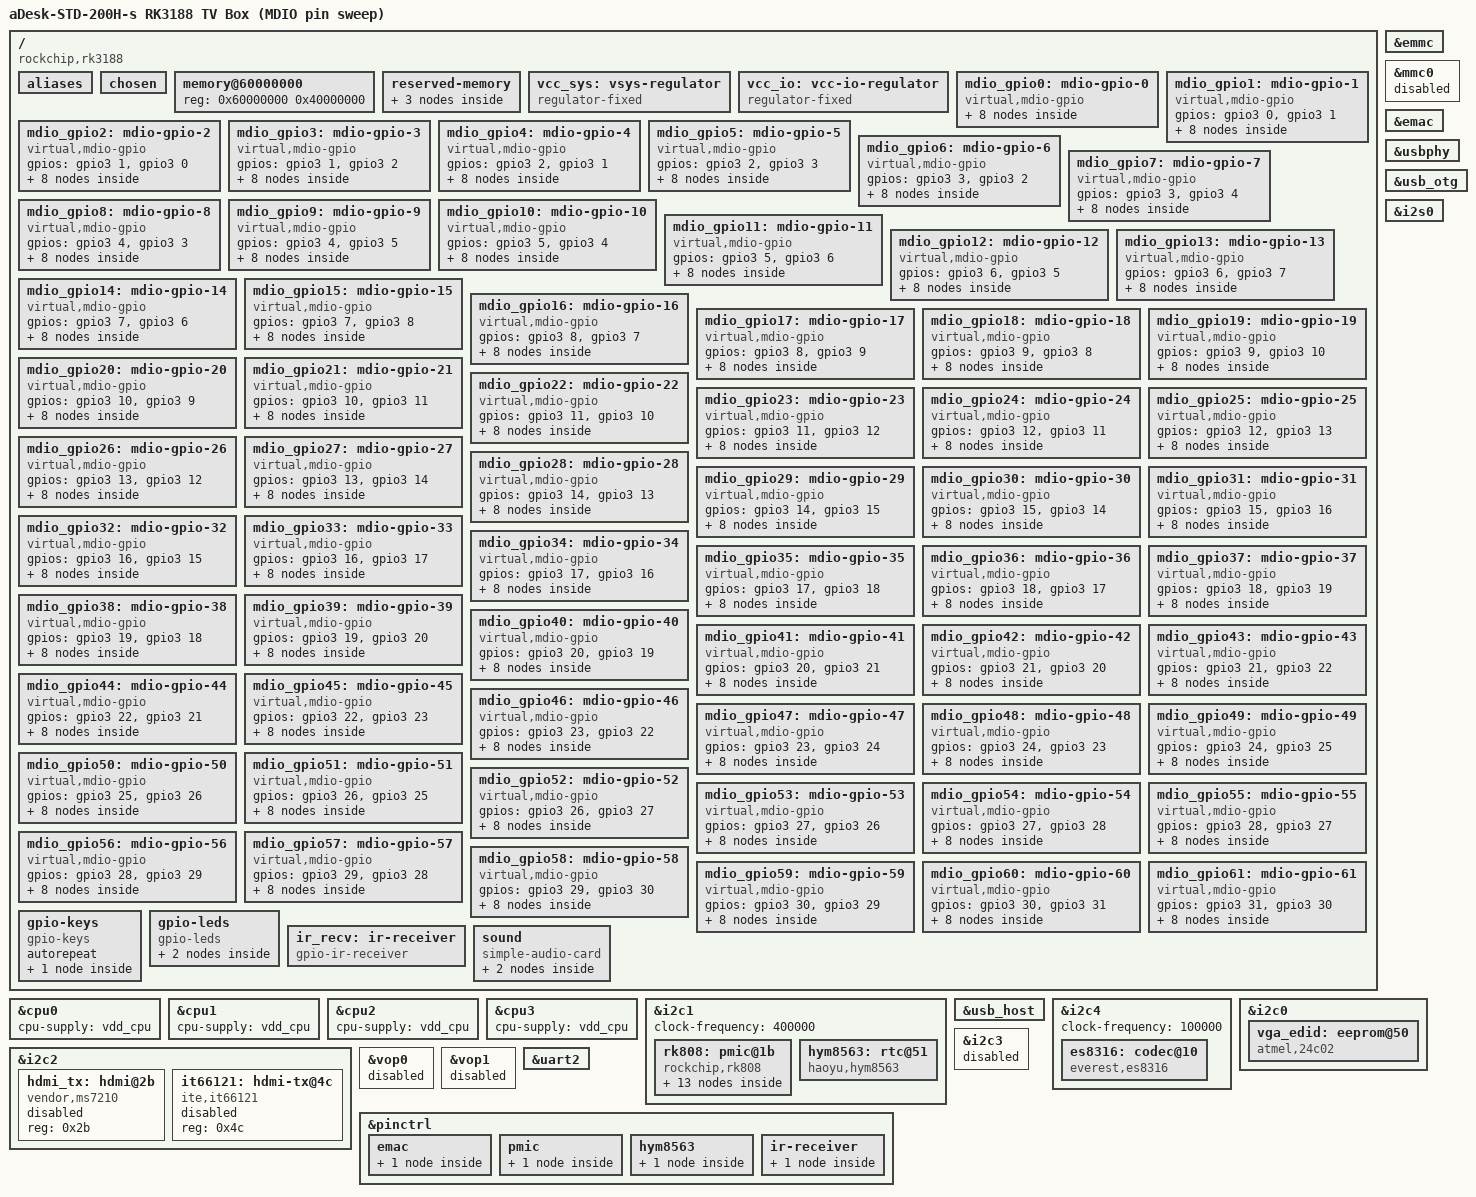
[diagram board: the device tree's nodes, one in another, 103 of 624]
// SPDX-License-Identifier: (GPL-2.0+ OR MIT)
/dts-v1/;
/*
 * 【诊断专用】MDIO 引脚扫频版（不是最终版）
 * 背景：RTL8201FN 在 GPIO3_D0/D1 上，硬件 MDIO（ttl-17）和软件 bit-bang（ttl-19）
 * 都扫不到 0~7 任一地址；而 RJ45 指示灯亮，说明 PHY 有电、链路正常。
 * 做法：在 GPIO3 组（pin 96~127 = A0~D7）内，把所有【相邻引脚对】的正反两种极性
 * 各挂一条 mdio-gpio 总线（共 62 条），每条都扫 0~7 号地址。
 * 判读：哪一条总线打出“不是 missing”的地址，那两只脚就是真的 MDC/MDIO，
 * 且那个地址就是 PHY 真实地址。找到后改回单总线正式版。
 */

#include <dt-bindings/gpio/gpio.h>
#include <dt-bindings/input/input.h>
#include <dt-bindings/interrupt-controller/irq.h>
#include <dt-bindings/pinctrl/rockchip.h>
#include "rk3188.dtsi"

/ {
	model = "aDesk-STD-200H-s RK3188 TV Box (MDIO pin sweep)";
	compatible = "rockchip,rk3188";

	aliases {
		/* 物理 TTL 接 UART2（0x20064000）；uart2 由 dtsi 默认 alias serial2 映射为 ttyS2 */
		serial0 = &uart0;
		serial2 = &uart2;
		/* mdio-gpio 总线别名：驱动靠它取 bus id（of_alias_get_id(node,"mdio-gpio")），
		 * 没有这行只会打印一句 failed to get alias id 然后 id=0，功能不受影响 */
		mdio-gpio0 = &mdio_gpio0;
		mdio-gpio1 = &mdio_gpio1;
		mdio-gpio2 = &mdio_gpio2;
		mdio-gpio3 = &mdio_gpio3;
		mdio-gpio4 = &mdio_gpio4;
		mdio-gpio5 = &mdio_gpio5;
		mdio-gpio6 = &mdio_gpio6;
		mdio-gpio7 = &mdio_gpio7;
		mdio-gpio8 = &mdio_gpio8;
		mdio-gpio9 = &mdio_gpio9;
		mdio-gpio10 = &mdio_gpio10;
		mdio-gpio11 = &mdio_gpio11;
		mdio-gpio12 = &mdio_gpio12;
		mdio-gpio13 = &mdio_gpio13;
		mdio-gpio14 = &mdio_gpio14;
		mdio-gpio15 = &mdio_gpio15;
		mdio-gpio16 = &mdio_gpio16;
		mdio-gpio17 = &mdio_gpio17;
		mdio-gpio18 = &mdio_gpio18;
		mdio-gpio19 = &mdio_gpio19;
		mdio-gpio20 = &mdio_gpio20;
		mdio-gpio21 = &mdio_gpio21;
		mdio-gpio22 = &mdio_gpio22;
		mdio-gpio23 = &mdio_gpio23;
		mdio-gpio24 = &mdio_gpio24;
		mdio-gpio25 = &mdio_gpio25;
		mdio-gpio26 = &mdio_gpio26;
		mdio-gpio27 = &mdio_gpio27;
		mdio-gpio28 = &mdio_gpio28;
		mdio-gpio29 = &mdio_gpio29;
		mdio-gpio30 = &mdio_gpio30;
		mdio-gpio31 = &mdio_gpio31;
		mdio-gpio32 = &mdio_gpio32;
		mdio-gpio33 = &mdio_gpio33;
		mdio-gpio34 = &mdio_gpio34;
		mdio-gpio35 = &mdio_gpio35;
		mdio-gpio36 = &mdio_gpio36;
		mdio-gpio37 = &mdio_gpio37;
		mdio-gpio38 = &mdio_gpio38;
		mdio-gpio39 = &mdio_gpio39;
		mdio-gpio40 = &mdio_gpio40;
		mdio-gpio41 = &mdio_gpio41;
		mdio-gpio42 = &mdio_gpio42;
		mdio-gpio43 = &mdio_gpio43;
		mdio-gpio44 = &mdio_gpio44;
		mdio-gpio45 = &mdio_gpio45;
		mdio-gpio46 = &mdio_gpio46;
		mdio-gpio47 = &mdio_gpio47;
		mdio-gpio48 = &mdio_gpio48;
		mdio-gpio49 = &mdio_gpio49;
		mdio-gpio50 = &mdio_gpio50;
		mdio-gpio51 = &mdio_gpio51;
		mdio-gpio52 = &mdio_gpio52;
		mdio-gpio53 = &mdio_gpio53;
		mdio-gpio54 = &mdio_gpio54;
		mdio-gpio55 = &mdio_gpio55;
		mdio-gpio56 = &mdio_gpio56;
		mdio-gpio57 = &mdio_gpio57;
		mdio-gpio58 = &mdio_gpio58;
		mdio-gpio59 = &mdio_gpio59;
		mdio-gpio60 = &mdio_gpio60;
		mdio-gpio61 = &mdio_gpio61;
		mmc0 = &mmc0;   /* SD 卡控制器（本机无卡槽，节点已 disabled，别名保留仅占位） */
		mmc1 = &emmc;   /* eMMC 控制器：这条别名决定它固定是 mmc1 → /dev/mmcblk1，
		                   必须保留，否则 root=/dev/mmcblk1p1 会失效 */
	};

	chosen {
		/* 修正：console/stdout 对齐物理串口 UART2（ttyS2）；原 serial0/uart0 是误改
		 *
		 * 【第五轮 DTS 改动 2/2：bootargs 与 parameter.txt 的 CMDLINE 完全对齐】
		 * 原代码：
		 *   bootargs = "console=ttyS2,115200 earlyprintk loglevel=8";
		 * 只带 console，没有 root= / blkdevparts。
		 *
		 * 为什么要在 DT 里也写一份？
		 *   内核配置里有 CONFIG_ARM_ATAG_DTB_COMPAT_CMDLINE_FROM_BOOTLOADER=y，
		 *   正常路径是 loader 把 parameter.txt 的 CMDLINE 通过 ATAG 传进来并覆盖
		 *   这里的 bootargs（所以上一轮日志里的 CMDLINE 一直等于 parameter 内容）。
		 *   但一旦 loader 没传 ATAG（换 loader / 换刷机模式 / parameter 没被选中），
		 *   内核就会退回到吃这里的 bootargs —— 没有 root= 和 blkdevparts 时
		 *   又必然 panic。这里写同一份完整串，等于给内核留一条备用路径。
		 *   两处内容必须一字不差地保持同步（build.yml 已从 parameter.txt 里读取
		 *   CMDLINE 直接写进 boot.img 头，CI 还会比对，防止两边漂移）。
		 *
		 * blkdevparts=mmcblk1:-@24M(rootfs)：
		 *   eMMC 上没有 MBR/GPT（ttl-rz4 的 unknown-block(179,1) 已证明），
		 *   由内核 block/partitions/cmdline.c 按命令行建分区：
		 *   在 mmcblk1 上、从 24MiB 起、到盘尾，建 1 个名为 rootfs 的分区，
		 *   即 /dev/mmcblk1p1。生效前提是 CONFIG_PARTITION_ADVANCED=y +
		 *   CONFIG_CMDLINE_PARTITION=y（build.yml 编译期已强制校验）。
		 *   注意 "-" 是“剩余全部”，单位字节。
		 *
		 *   【4MiB 这个数字的来历（对照教程日志）】
		 *   教程 TTL 里有：
		 *     mmcblk0boot0: mmc0:0001 Biwin 4.00 MiB
		 *     mmcblk0boot1: mmc0:0001 Biwin 4.00 MiB
		 *   这是 eMMC 的两个**硬件 boot 分区**的尺寸（那片 Biwin 是 4MiB，本机
		 *   的 004GA1 是 2MiB），与 rootfs 偏移无关，不用管。
		 *   真正与偏移有关的是 parameter 里的 0x2000：扇区单位 ×512 = 4MiB，
		 *   这是加载器/parameter 自身的保留区（loader 就写在扇区 0 起），
		 *   所以 boot 从 4MiB 开始、长 16MiB，到 20MiB(0xA000) 结束。
		 *   教程的 rootfs 正是紧接其后 @0xA000 —— 首尾相接，中间没有空洞。
		 *
		 *   【第八/九轮踩过的坑】
		 *   ttl-rz8：rootfs 声明 0xA000，救援 init 逐偏移读 ext4 超级块，只有
		 *   24MiB（25165824）命中（卷标 rootfs），20MiB 处是残留的 "ANDROID!" 头。
		 *   ttl-rz9：把声明挪到 0xC000 后，数据又跑到 28MiB；而 24MiB 那份变成
		 *   "超级块还在、日志区被覆盖"的废拷贝，挂载报：
		 *     JBD2: no valid journal superblock found
		 *     EXT4-fs (mmcblk1p1): Could not load journal inode
		 *   两轮实测的规律是固定 +4MiB：工具写盘位置 = 声明偏移 + 0x2000 扇区。
		 *   既然规律是死的，就把声明挪回教程同款的 0xA000，让数据落回 24MiB。
		 *
		 *   【第十轮：实现存储对齐】
		 *       boot    0x2000 .. 0xA000（4MiB~20MiB，容量 16MiB）
		 *       rootfs  声明 0xA000(20MiB) → 工具 +4MiB → 数据落 24MiB
		 *       内核    @24M            → p1 起点 = 24MiB = 数据起点
		 *   三处数字固定成 20MiB/24MiB 这组关系：声明→实际→内核视图一条线，
		 *   24MiB 是 4MiB 整数倍（对 eMMC 擦除块/页对齐友好），
		 *   且 24MiB 是**唯一被实机成功挂载过**的偏移（ttl-rz8：losetup -o
		 *   25165824 + mount 成功，df 报 973.4M 总/288.8M 已用）。
		 *   原值（第九轮，保留备查）：blkdevparts=mmcblk1:-@28M(rootfs)
		 *          + mtdparts ...-@0x0000C000(rootfs)
		 */
		stdout-path = "serial2:115200n8";
		// 【第七轮改动：bootargs 补 initrd=0x62000000,0x00800000，与 parameter.txt 的 CMDLINE 逐字对齐】
		// 原因：ttl-rz7 里 boot.img 头带了 ramdisk（头校验 ramdisk_addr=0x62000000、
		// ramdisk_size>0），但内核完全没有 unpack initramfs 的动作，直接进 mount_root
		// 然后 panic —— 说明 loader 没把 ramdisk 交给内核。原厂 parameter-bibl.txt 的
		// CMDLINE 里正是有 initrd=0x62000000,0x00800000，它是 RK31 loader "把 ramdisk
		// 搬到 0x62000000" 的指令。loader 会用自己的 CMDLINE 覆盖这里（ATAG_FROM_
		// BOOTLOADER），所以两边必须同步；平时以 parameter.txt 为准。
		// 原值（保留备查；第七轮时的形态：无 initrd=，rootfs 起点 20M = 0xA000）：
		// bootargs = "console=ttyS2,115200 earlyprintk root=/dev/mmcblk1p1 rootfstype=ext4 rw rootwait init=/sbin/init maxcpus=1 blkdevparts=mmcblk1:-@20M(rootfs)";
		// 原值（第九轮，保留备查）：blkdevparts=mmcblk1:-@28M(rootfs)（本轮回到 @24M，见上方注释）
		// 原值（第十轮，保留备查）：... init=/sbin/init initrd=0x62000000,0x00800000 maxcpus=1 ...
		// 【ttl-rz10 改动：去掉 initrd=0x62000000,0x00800000】
		// 主刷的 boot.img 是纯内核（没有 ramdisk），但 CMDLINE 里带 initrd= 会让
		// loader 在 0x62000000 上交给内核一段 192K 残留垃圾，内核就去"解 initramfs"
		// → "junk within compressed archive" 失败 → 跳过挂根 → exec /init(ENOENT)
		// → exec /sbin/init(ENOENT) → panic（ttl-rz10 实测）。
		// 去掉后内核对 initramfs 不再有期待，会正常执行挂根流程。
		// 只有刷 boot-rescue.img（带救援 initramfs）时才需要它，那份走
		// parameter-rescue.txt，不改这里（这里的 bootargs 是 loader 不传 ATAG 时的兜底）。
		bootargs = "console=ttyS2,115200 earlyprintk root=/dev/mmcblk1p1 rootfstype=ext4 rw rootwait init=/sbin/init maxcpus=1 blkdevparts=mmcblk1:-@24M(rootfs)";
	};

	memory@60000000 {
		device_type = "memory";
		reg = <0x60000000 0x40000000>; /* 1GB DDR3 */
	};

	reserved-memory {
		#address-cells = <1>;
		#size-cells = <1>;
		ranges;
		ion1: ion@88400000 { reg = <0x88400000 0x06400000>; no-map; };
		ion2: ion@7ee00000 { reg = <0x7ee00000 0x09600000>; no-map; };
		fb: framebuffer@7a600000 { reg = <0x7a600000 0x04800000>; no-map; };
	};

	vcc_sys: vsys-regulator {
		compatible = "regulator-fixed";
		regulator-name = "vsys";
		regulator-min-microvolt = <5000000>;
		regulator-max-microvolt = <5000000>;
		regulator-boot-on;
	};

	vcc_io: vcc-io-regulator {
		compatible = "regulator-fixed";
		regulator-name = "vcc_io";
		regulator-min-microvolt = <3300000>;
		regulator-max-microvolt = <3300000>;
		regulator-always-on;
	};

	/* ============================================================
	 * 第二十三轮：MDIO 改成 GPIO 软件模拟总线（bit-bang）
	 * ============================================================
	 * 依据一（原厂固件）：从原机 kernel.img 里提取到的字符串是
	 *   mdio_bb_read / mdio_bb_write              → 原厂就是软件 bit-bang
	 *   "request mdio pin ok" / "request mdc pin ok" → 把两只脚当 GPIO 申请
	 *   "output mdio ctl pin ok , enable rtl8201f ethernet function"
	 * 依据二（实机）：ttl-16/ttl-17 用 SoC 硬件 MDIO 读 RTL8201FN，0~7 号地址
	 * 全部 missing，每次超时约 33ms（读到的是上拉电平 0xffff）；而 RJ45 指示灯是亮的，
	 * 说明 PHY 有电、链路正常，只是管理口这条通路没通。
	 *
	 * 做法：GPIO3_D0/D1 从 EMAC 复用功能改成 GPIO，交给内核 mdio-gpio 驱动
	 * 用软件时序扫描；速率由软件决定，远低于 RTL8201FN 的 MDC 上限 2.5MHz。
	 * 同时把 0~7 全部地址都声明出来：一次启动既验证通路，又直接定位 PHY 地址。
	 */
	/* [00] MDC=GPIO3_D1(121)  MDIO=GPIO3_D0(120) */
	mdio_gpio0: mdio-gpio-0 {
		compatible = "virtual,mdio-gpio";
		#address-cells = <1>;
		#size-cells = <0>;
		gpios = <&gpio3 25 GPIO_ACTIVE_HIGH>,
		        <&gpio3 24 GPIO_ACTIVE_HIGH>;
		/* 只给第 0 条（D1/D0，与 ttl-19 完全同条件）配上拉，保证可复现对照 */
		pinctrl-names = "default";
		pinctrl-0 = <&emac_mdio_gpio>;
		phy0: ethernet-phy@0 { reg = <0>; };
		ethernet-phy@1 { reg = <1>; };
		ethernet-phy@2 { reg = <2>; };
		ethernet-phy@3 { reg = <3>; };
		ethernet-phy@4 { reg = <4>; };
		ethernet-phy@5 { reg = <5>; };
		ethernet-phy@6 { reg = <6>; };
		ethernet-phy@7 { reg = <7>; };
	};

	/* [01] MDC=GPIO3_A0(96)  MDIO=GPIO3_A1(97) */
	mdio_gpio1: mdio-gpio-1 {
		compatible = "virtual,mdio-gpio";
		#address-cells = <1>;
		#size-cells = <0>;
		gpios = <&gpio3 0 GPIO_ACTIVE_HIGH>,
		        <&gpio3 1 GPIO_ACTIVE_HIGH>;
		ethernet-phy@0 { reg = <0>; };
		ethernet-phy@1 { reg = <1>; };
		ethernet-phy@2 { reg = <2>; };
		ethernet-phy@3 { reg = <3>; };
		ethernet-phy@4 { reg = <4>; };
		ethernet-phy@5 { reg = <5>; };
		ethernet-phy@6 { reg = <6>; };
		ethernet-phy@7 { reg = <7>; };
	};

	/* [02] MDC=GPIO3_A1(97)  MDIO=GPIO3_A0(96) */
	mdio_gpio2: mdio-gpio-2 {
		compatible = "virtual,mdio-gpio";
		#address-cells = <1>;
		#size-cells = <0>;
		gpios = <&gpio3 1 GPIO_ACTIVE_HIGH>,
		        <&gpio3 0 GPIO_ACTIVE_HIGH>;
		ethernet-phy@0 { reg = <0>; };
		ethernet-phy@1 { reg = <1>; };
		ethernet-phy@2 { reg = <2>; };
		ethernet-phy@3 { reg = <3>; };
		ethernet-phy@4 { reg = <4>; };
		ethernet-phy@5 { reg = <5>; };
		ethernet-phy@6 { reg = <6>; };
		ethernet-phy@7 { reg = <7>; };
	};

	/* [03] MDC=GPIO3_A1(97)  MDIO=GPIO3_A2(98) */
	mdio_gpio3: mdio-gpio-3 {
		compatible = "virtual,mdio-gpio";
		#address-cells = <1>;
		#size-cells = <0>;
		gpios = <&gpio3 1 GPIO_ACTIVE_HIGH>,
		        <&gpio3 2 GPIO_ACTIVE_HIGH>;
		ethernet-phy@0 { reg = <0>; };
		ethernet-phy@1 { reg = <1>; };
		ethernet-phy@2 { reg = <2>; };
		ethernet-phy@3 { reg = <3>; };
		ethernet-phy@4 { reg = <4>; };
		ethernet-phy@5 { reg = <5>; };
		ethernet-phy@6 { reg = <6>; };
		ethernet-phy@7 { reg = <7>; };
	};

	/* [04] MDC=GPIO3_A2(98)  MDIO=GPIO3_A1(97) */
	mdio_gpio4: mdio-gpio-4 {
		compatible = "virtual,mdio-gpio";
		#address-cells = <1>;
		#size-cells = <0>;
		gpios = <&gpio3 2 GPIO_ACTIVE_HIGH>,
		        <&gpio3 1 GPIO_ACTIVE_HIGH>;
		ethernet-phy@0 { reg = <0>; };
		ethernet-phy@1 { reg = <1>; };
		ethernet-phy@2 { reg = <2>; };
		ethernet-phy@3 { reg = <3>; };
		ethernet-phy@4 { reg = <4>; };
		ethernet-phy@5 { reg = <5>; };
		ethernet-phy@6 { reg = <6>; };
		ethernet-phy@7 { reg = <7>; };
	};

	/* [05] MDC=GPIO3_A2(98)  MDIO=GPIO3_A3(99) */
	mdio_gpio5: mdio-gpio-5 {
		compatible = "virtual,mdio-gpio";
		#address-cells = <1>;
		#size-cells = <0>;
		gpios = <&gpio3 2 GPIO_ACTIVE_HIGH>,
		        <&gpio3 3 GPIO_ACTIVE_HIGH>;
		ethernet-phy@0 { reg = <0>; };
		ethernet-phy@1 { reg = <1>; };
		ethernet-phy@2 { reg = <2>; };
		ethernet-phy@3 { reg = <3>; };
		ethernet-phy@4 { reg = <4>; };
		ethernet-phy@5 { reg = <5>; };
		ethernet-phy@6 { reg = <6>; };
		ethernet-phy@7 { reg = <7>; };
	};

	/* [06] MDC=GPIO3_A3(99)  MDIO=GPIO3_A2(98) */
	mdio_gpio6: mdio-gpio-6 {
		compatible = "virtual,mdio-gpio";
		#address-cells = <1>;
		#size-cells = <0>;
		gpios = <&gpio3 3 GPIO_ACTIVE_HIGH>,
		        <&gpio3 2 GPIO_ACTIVE_HIGH>;
		ethernet-phy@0 { reg = <0>; };
		ethernet-phy@1 { reg = <1>; };
		ethernet-phy@2 { reg = <2>; };
		ethernet-phy@3 { reg = <3>; };
		ethernet-phy@4 { reg = <4>; };
		ethernet-phy@5 { reg = <5>; };
		ethernet-phy@6 { reg = <6>; };
		ethernet-phy@7 { reg = <7>; };
	};

	/* [07] MDC=GPIO3_A3(99)  MDIO=GPIO3_A4(100) */
	mdio_gpio7: mdio-gpio-7 {
		compatible = "virtual,mdio-gpio";
		#address-cells = <1>;
		#size-cells = <0>;
		gpios = <&gpio3 3 GPIO_ACTIVE_HIGH>,
		        <&gpio3 4 GPIO_ACTIVE_HIGH>;
		ethernet-phy@0 { reg = <0>; };
		ethernet-phy@1 { reg = <1>; };
		ethernet-phy@2 { reg = <2>; };
		ethernet-phy@3 { reg = <3>; };
		ethernet-phy@4 { reg = <4>; };
		ethernet-phy@5 { reg = <5>; };
		ethernet-phy@6 { reg = <6>; };
		ethernet-phy@7 { reg = <7>; };
	};

	/* [08] MDC=GPIO3_A4(100)  MDIO=GPIO3_A3(99) */
	mdio_gpio8: mdio-gpio-8 {
		compatible = "virtual,mdio-gpio";
		#address-cells = <1>;
		#size-cells = <0>;
		gpios = <&gpio3 4 GPIO_ACTIVE_HIGH>,
		        <&gpio3 3 GPIO_ACTIVE_HIGH>;
		ethernet-phy@0 { reg = <0>; };
		ethernet-phy@1 { reg = <1>; };
		ethernet-phy@2 { reg = <2>; };
		ethernet-phy@3 { reg = <3>; };
		ethernet-phy@4 { reg = <4>; };
		ethernet-phy@5 { reg = <5>; };
		ethernet-phy@6 { reg = <6>; };
		ethernet-phy@7 { reg = <7>; };
	};

	/* [09] MDC=GPIO3_A4(100)  MDIO=GPIO3_A5(101) */
	mdio_gpio9: mdio-gpio-9 {
		compatible = "virtual,mdio-gpio";
		#address-cells = <1>;
		#size-cells = <0>;
		gpios = <&gpio3 4 GPIO_ACTIVE_HIGH>,
		        <&gpio3 5 GPIO_ACTIVE_HIGH>;
		ethernet-phy@0 { reg = <0>; };
		ethernet-phy@1 { reg = <1>; };
		ethernet-phy@2 { reg = <2>; };
		ethernet-phy@3 { reg = <3>; };
		ethernet-phy@4 { reg = <4>; };
		ethernet-phy@5 { reg = <5>; };
		ethernet-phy@6 { reg = <6>; };
		ethernet-phy@7 { reg = <7>; };
	};

	/* [10] MDC=GPIO3_A5(101)  MDIO=GPIO3_A4(100) */
	mdio_gpio10: mdio-gpio-10 {
		compatible = "virtual,mdio-gpio";
		#address-cells = <1>;
		#size-cells = <0>;
		gpios = <&gpio3 5 GPIO_ACTIVE_HIGH>,
		        <&gpio3 4 GPIO_ACTIVE_HIGH>;
		ethernet-phy@0 { reg = <0>; };
		ethernet-phy@1 { reg = <1>; };
		ethernet-phy@2 { reg = <2>; };
		ethernet-phy@3 { reg = <3>; };
		ethernet-phy@4 { reg = <4>; };
		ethernet-phy@5 { reg = <5>; };
		ethernet-phy@6 { reg = <6>; };
		ethernet-phy@7 { reg = <7>; };
	};

	/* [11] MDC=GPIO3_A5(101)  MDIO=GPIO3_A6(102) */
	mdio_gpio11: mdio-gpio-11 {
		compatible = "virtual,mdio-gpio";
		#address-cells = <1>;
		#size-cells = <0>;
		gpios = <&gpio3 5 GPIO_ACTIVE_HIGH>,
		        <&gpio3 6 GPIO_ACTIVE_HIGH>;
		ethernet-phy@0 { reg = <0>; };
		ethernet-phy@1 { reg = <1>; };
		ethernet-phy@2 { reg = <2>; };
		ethernet-phy@3 { reg = <3>; };
		ethernet-phy@4 { reg = <4>; };
		ethernet-phy@5 { reg = <5>; };
		ethernet-phy@6 { reg = <6>; };
		ethernet-phy@7 { reg = <7>; };
	};

	/* [12] MDC=GPIO3_A6(102)  MDIO=GPIO3_A5(101) */
	mdio_gpio12: mdio-gpio-12 {
		compatible = "virtual,mdio-gpio";
		#address-cells = <1>;
		#size-cells = <0>;
		gpios = <&gpio3 6 GPIO_ACTIVE_HIGH>,
		        <&gpio3 5 GPIO_ACTIVE_HIGH>;
		ethernet-phy@0 { reg = <0>; };
		ethernet-phy@1 { reg = <1>; };
		ethernet-phy@2 { reg = <2>; };
		ethernet-phy@3 { reg = <3>; };
		ethernet-phy@4 { reg = <4>; };
		ethernet-phy@5 { reg = <5>; };
		ethernet-phy@6 { reg = <6>; };
		ethernet-phy@7 { reg = <7>; };
	};

	/* [13] MDC=GPIO3_A6(102)  MDIO=GPIO3_A7(103) */
	mdio_gpio13: mdio-gpio-13 {
		compatible = "virtual,mdio-gpio";
		#address-cells = <1>;
		#size-cells = <0>;
		gpios = <&gpio3 6 GPIO_ACTIVE_HIGH>,
		        <&gpio3 7 GPIO_ACTIVE_HIGH>;
		ethernet-phy@0 { reg = <0>; };
		ethernet-phy@1 { reg = <1>; };
		ethernet-phy@2 { reg = <2>; };
		ethernet-phy@3 { reg = <3>; };
		ethernet-phy@4 { reg = <4>; };
		ethernet-phy@5 { reg = <5>; };
		ethernet-phy@6 { reg = <6>; };
		ethernet-phy@7 { reg = <7>; };
	};

	/* [14] MDC=GPIO3_A7(103)  MDIO=GPIO3_A6(102) */
	mdio_gpio14: mdio-gpio-14 {
		compatible = "virtual,mdio-gpio";
		#address-cells = <1>;
		#size-cells = <0>;
		gpios = <&gpio3 7 GPIO_ACTIVE_HIGH>,
		        <&gpio3 6 GPIO_ACTIVE_HIGH>;
		ethernet-phy@0 { reg = <0>; };
		ethernet-phy@1 { reg = <1>; };
		ethernet-phy@2 { reg = <2>; };
		ethernet-phy@3 { reg = <3>; };
		ethernet-phy@4 { reg = <4>; };
		ethernet-phy@5 { reg = <5>; };
		ethernet-phy@6 { reg = <6>; };
		ethernet-phy@7 { reg = <7>; };
	};

	/* [15] MDC=GPIO3_A7(103)  MDIO=GPIO3_B0(104) */
	mdio_gpio15: mdio-gpio-15 {
		compatible = "virtual,mdio-gpio";
		#address-cells = <1>;
		#size-cells = <0>;
		gpios = <&gpio3 7 GPIO_ACTIVE_HIGH>,
		        <&gpio3 8 GPIO_ACTIVE_HIGH>;
		ethernet-phy@0 { reg = <0>; };
		ethernet-phy@1 { reg = <1>; };
		ethernet-phy@2 { reg = <2>; };
		ethernet-phy@3 { reg = <3>; };
		ethernet-phy@4 { reg = <4>; };
		ethernet-phy@5 { reg = <5>; };
		ethernet-phy@6 { reg = <6>; };
		ethernet-phy@7 { reg = <7>; };
	};

	/* [16] MDC=GPIO3_B0(104)  MDIO=GPIO3_A7(103) */
	mdio_gpio16: mdio-gpio-16 {
		compatible = "virtual,mdio-gpio";
		#address-cells = <1>;
		#size-cells = <0>;
		gpios = <&gpio3 8 GPIO_ACTIVE_HIGH>,
		        <&gpio3 7 GPIO_ACTIVE_HIGH>;
		ethernet-phy@0 { reg = <0>; };
		ethernet-phy@1 { reg = <1>; };
		ethernet-phy@2 { reg = <2>; };
		ethernet-phy@3 { reg = <3>; };
		ethernet-phy@4 { reg = <4>; };
		ethernet-phy@5 { reg = <5>; };
		ethernet-phy@6 { reg = <6>; };
		ethernet-phy@7 { reg = <7>; };
	};

	/* [17] MDC=GPIO3_B0(104)  MDIO=GPIO3_B1(105) */
	mdio_gpio17: mdio-gpio-17 {
		compatible = "virtual,mdio-gpio";
		#address-cells = <1>;
		#size-cells = <0>;
		gpios = <&gpio3 8 GPIO_ACTIVE_HIGH>,
		        <&gpio3 9 GPIO_ACTIVE_HIGH>;
		ethernet-phy@0 { reg = <0>; };
		ethernet-phy@1 { reg = <1>; };
		ethernet-phy@2 { reg = <2>; };
		ethernet-phy@3 { reg = <3>; };
		ethernet-phy@4 { reg = <4>; };
		ethernet-phy@5 { reg = <5>; };
		ethernet-phy@6 { reg = <6>; };
		ethernet-phy@7 { reg = <7>; };
	};

	/* [18] MDC=GPIO3_B1(105)  MDIO=GPIO3_B0(104) */
	mdio_gpio18: mdio-gpio-18 {
		compatible = "virtual,mdio-gpio";
		#address-cells = <1>;
		#size-cells = <0>;
		gpios = <&gpio3 9 GPIO_ACTIVE_HIGH>,
		        <&gpio3 8 GPIO_ACTIVE_HIGH>;
		ethernet-phy@0 { reg = <0>; };
		ethernet-phy@1 { reg = <1>; };
		ethernet-phy@2 { reg = <2>; };
		ethernet-phy@3 { reg = <3>; };
		ethernet-phy@4 { reg = <4>; };
		ethernet-phy@5 { reg = <5>; };
		ethernet-phy@6 { reg = <6>; };
		ethernet-phy@7 { reg = <7>; };
	};

	/* [19] MDC=GPIO3_B1(105)  MDIO=GPIO3_B2(106) */
	mdio_gpio19: mdio-gpio-19 {
		compatible = "virtual,mdio-gpio";
		#address-cells = <1>;
		#size-cells = <0>;
		gpios = <&gpio3 9 GPIO_ACTIVE_HIGH>,
		        <&gpio3 10 GPIO_ACTIVE_HIGH>;
		ethernet-phy@0 { reg = <0>; };
		ethernet-phy@1 { reg = <1>; };
		ethernet-phy@2 { reg = <2>; };
		ethernet-phy@3 { reg = <3>; };
		ethernet-phy@4 { reg = <4>; };
		ethernet-phy@5 { reg = <5>; };
		ethernet-phy@6 { reg = <6>; };
		ethernet-phy@7 { reg = <7>; };
	};

	/* [20] MDC=GPIO3_B2(106)  MDIO=GPIO3_B1(105) */
	mdio_gpio20: mdio-gpio-20 {
		compatible = "virtual,mdio-gpio";
		#address-cells = <1>;
		#size-cells = <0>;
		gpios = <&gpio3 10 GPIO_ACTIVE_HIGH>,
		        <&gpio3 9 GPIO_ACTIVE_HIGH>;
		ethernet-phy@0 { reg = <0>; };
		ethernet-phy@1 { reg = <1>; };
		ethernet-phy@2 { reg = <2>; };
		ethernet-phy@3 { reg = <3>; };
		ethernet-phy@4 { reg = <4>; };
		ethernet-phy@5 { reg = <5>; };
		ethernet-phy@6 { reg = <6>; };
		ethernet-phy@7 { reg = <7>; };
	};

	/* [21] MDC=GPIO3_B2(106)  MDIO=GPIO3_B3(107) */
	mdio_gpio21: mdio-gpio-21 {
		compatible = "virtual,mdio-gpio";
		#address-cells = <1>;
		#size-cells = <0>;
		gpios = <&gpio3 10 GPIO_ACTIVE_HIGH>,
		        <&gpio3 11 GPIO_ACTIVE_HIGH>;
		ethernet-phy@0 { reg = <0>; };
		ethernet-phy@1 { reg = <1>; };
		ethernet-phy@2 { reg = <2>; };
		ethernet-phy@3 { reg = <3>; };
		ethernet-phy@4 { reg = <4>; };
		ethernet-phy@5 { reg = <5>; };
		ethernet-phy@6 { reg = <6>; };
		ethernet-phy@7 { reg = <7>; };
	};

	/* [22] MDC=GPIO3_B3(107)  MDIO=GPIO3_B2(106) */
	mdio_gpio22: mdio-gpio-22 {
		compatible = "virtual,mdio-gpio";
		#address-cells = <1>;
		#size-cells = <0>;
		gpios = <&gpio3 11 GPIO_ACTIVE_HIGH>,
		        <&gpio3 10 GPIO_ACTIVE_HIGH>;
		ethernet-phy@0 { reg = <0>; };
		ethernet-phy@1 { reg = <1>; };
		ethernet-phy@2 { reg = <2>; };
		ethernet-phy@3 { reg = <3>; };
		ethernet-phy@4 { reg = <4>; };
		ethernet-phy@5 { reg = <5>; };
		ethernet-phy@6 { reg = <6>; };
		ethernet-phy@7 { reg = <7>; };
	};

	/* [23] MDC=GPIO3_B3(107)  MDIO=GPIO3_B4(108) */
	mdio_gpio23: mdio-gpio-23 {
		compatible = "virtual,mdio-gpio";
		#address-cells = <1>;
		#size-cells = <0>;
		gpios = <&gpio3 11 GPIO_ACTIVE_HIGH>,
		        <&gpio3 12 GPIO_ACTIVE_HIGH>;
		ethernet-phy@0 { reg = <0>; };
		ethernet-phy@1 { reg = <1>; };
		ethernet-phy@2 { reg = <2>; };
		ethernet-phy@3 { reg = <3>; };
		ethernet-phy@4 { reg = <4>; };
		ethernet-phy@5 { reg = <5>; };
		ethernet-phy@6 { reg = <6>; };
		ethernet-phy@7 { reg = <7>; };
	};

	/* [24] MDC=GPIO3_B4(108)  MDIO=GPIO3_B3(107) */
	mdio_gpio24: mdio-gpio-24 {
		compatible = "virtual,mdio-gpio";
		#address-cells = <1>;
		#size-cells = <0>;
		gpios = <&gpio3 12 GPIO_ACTIVE_HIGH>,
		        <&gpio3 11 GPIO_ACTIVE_HIGH>;
		ethernet-phy@0 { reg = <0>; };
		ethernet-phy@1 { reg = <1>; };
		ethernet-phy@2 { reg = <2>; };
		ethernet-phy@3 { reg = <3>; };
		ethernet-phy@4 { reg = <4>; };
		ethernet-phy@5 { reg = <5>; };
		ethernet-phy@6 { reg = <6>; };
		ethernet-phy@7 { reg = <7>; };
	};

	/* [25] MDC=GPIO3_B4(108)  MDIO=GPIO3_B5(109) */
	mdio_gpio25: mdio-gpio-25 {
		compatible = "virtual,mdio-gpio";
		#address-cells = <1>;
		#size-cells = <0>;
		gpios = <&gpio3 12 GPIO_ACTIVE_HIGH>,
		        <&gpio3 13 GPIO_ACTIVE_HIGH>;
		ethernet-phy@0 { reg = <0>; };
		ethernet-phy@1 { reg = <1>; };
		ethernet-phy@2 { reg = <2>; };
		ethernet-phy@3 { reg = <3>; };
		ethernet-phy@4 { reg = <4>; };
		ethernet-phy@5 { reg = <5>; };
		ethernet-phy@6 { reg = <6>; };
		ethernet-phy@7 { reg = <7>; };
	};

	/* [26] MDC=GPIO3_B5(109)  MDIO=GPIO3_B4(108) */
	mdio_gpio26: mdio-gpio-26 {
		compatible = "virtual,mdio-gpio";
		#address-cells = <1>;
		#size-cells = <0>;
		gpios = <&gpio3 13 GPIO_ACTIVE_HIGH>,
		        <&gpio3 12 GPIO_ACTIVE_HIGH>;
		ethernet-phy@0 { reg = <0>; };
		ethernet-phy@1 { reg = <1>; };
		ethernet-phy@2 { reg = <2>; };
		ethernet-phy@3 { reg = <3>; };
		ethernet-phy@4 { reg = <4>; };
		ethernet-phy@5 { reg = <5>; };
		ethernet-phy@6 { reg = <6>; };
		ethernet-phy@7 { reg = <7>; };
	};

	/* [27] MDC=GPIO3_B5(109)  MDIO=GPIO3_B6(110) */
	mdio_gpio27: mdio-gpio-27 {
		compatible = "virtual,mdio-gpio";
		#address-cells = <1>;
		#size-cells = <0>;
		gpios = <&gpio3 13 GPIO_ACTIVE_HIGH>,
		        <&gpio3 14 GPIO_ACTIVE_HIGH>;
		ethernet-phy@0 { reg = <0>; };
		ethernet-phy@1 { reg = <1>; };
		ethernet-phy@2 { reg = <2>; };
		ethernet-phy@3 { reg = <3>; };
		ethernet-phy@4 { reg = <4>; };
		ethernet-phy@5 { reg = <5>; };
		ethernet-phy@6 { reg = <6>; };
		ethernet-phy@7 { reg = <7>; };
	};

	/* [28] MDC=GPIO3_B6(110)  MDIO=GPIO3_B5(109) */
	mdio_gpio28: mdio-gpio-28 {
		compatible = "virtual,mdio-gpio";
		#address-cells = <1>;
		#size-cells = <0>;
		gpios = <&gpio3 14 GPIO_ACTIVE_HIGH>,
		        <&gpio3 13 GPIO_ACTIVE_HIGH>;
		ethernet-phy@0 { reg = <0>; };
		ethernet-phy@1 { reg = <1>; };
		ethernet-phy@2 { reg = <2>; };
		ethernet-phy@3 { reg = <3>; };
		ethernet-phy@4 { reg = <4>; };
		ethernet-phy@5 { reg = <5>; };
		ethernet-phy@6 { reg = <6>; };
		ethernet-phy@7 { reg = <7>; };
	};

	/* [29] MDC=GPIO3_B6(110)  MDIO=GPIO3_B7(111) */
	mdio_gpio29: mdio-gpio-29 {
		compatible = "virtual,mdio-gpio";
		#address-cells = <1>;
		#size-cells = <0>;
		gpios = <&gpio3 14 GPIO_ACTIVE_HIGH>,
		        <&gpio3 15 GPIO_ACTIVE_HIGH>;
		ethernet-phy@0 { reg = <0>; };
		ethernet-phy@1 { reg = <1>; };
		ethernet-phy@2 { reg = <2>; };
		ethernet-phy@3 { reg = <3>; };
		ethernet-phy@4 { reg = <4>; };
		ethernet-phy@5 { reg = <5>; };
		ethernet-phy@6 { reg = <6>; };
		ethernet-phy@7 { reg = <7>; };
	};

	/* [30] MDC=GPIO3_B7(111)  MDIO=GPIO3_B6(110) */
	mdio_gpio30: mdio-gpio-30 {
		compatible = "virtual,mdio-gpio";
		#address-cells = <1>;
		#size-cells = <0>;
		gpios = <&gpio3 15 GPIO_ACTIVE_HIGH>,
		        <&gpio3 14 GPIO_ACTIVE_HIGH>;
		ethernet-phy@0 { reg = <0>; };
		ethernet-phy@1 { reg = <1>; };
		ethernet-phy@2 { reg = <2>; };
		ethernet-phy@3 { reg = <3>; };
		ethernet-phy@4 { reg = <4>; };
		ethernet-phy@5 { reg = <5>; };
		ethernet-phy@6 { reg = <6>; };
		ethernet-phy@7 { reg = <7>; };
	};

	/* [31] MDC=GPIO3_B7(111)  MDIO=GPIO3_C0(112) */
	mdio_gpio31: mdio-gpio-31 {
		compatible = "virtual,mdio-gpio";
		#address-cells = <1>;
		#size-cells = <0>;
		gpios = <&gpio3 15 GPIO_ACTIVE_HIGH>,
		        <&gpio3 16 GPIO_ACTIVE_HIGH>;
		ethernet-phy@0 { reg = <0>; };
		ethernet-phy@1 { reg = <1>; };
		ethernet-phy@2 { reg = <2>; };
		ethernet-phy@3 { reg = <3>; };
		ethernet-phy@4 { reg = <4>; };
		ethernet-phy@5 { reg = <5>; };
		ethernet-phy@6 { reg = <6>; };
		ethernet-phy@7 { reg = <7>; };
	};

	/* [32] MDC=GPIO3_C0(112)  MDIO=GPIO3_B7(111) */
	mdio_gpio32: mdio-gpio-32 {
		compatible = "virtual,mdio-gpio";
		#address-cells = <1>;
		#size-cells = <0>;
		gpios = <&gpio3 16 GPIO_ACTIVE_HIGH>,
		        <&gpio3 15 GPIO_ACTIVE_HIGH>;
		ethernet-phy@0 { reg = <0>; };
		ethernet-phy@1 { reg = <1>; };
		ethernet-phy@2 { reg = <2>; };
		ethernet-phy@3 { reg = <3>; };
		ethernet-phy@4 { reg = <4>; };
		ethernet-phy@5 { reg = <5>; };
		ethernet-phy@6 { reg = <6>; };
		ethernet-phy@7 { reg = <7>; };
	};

	/* [33] MDC=GPIO3_C0(112)  MDIO=GPIO3_C1(113) */
	mdio_gpio33: mdio-gpio-33 {
		compatible = "virtual,mdio-gpio";
		#address-cells = <1>;
		#size-cells = <0>;
		gpios = <&gpio3 16 GPIO_ACTIVE_HIGH>,
		        <&gpio3 17 GPIO_ACTIVE_HIGH>;
		ethernet-phy@0 { reg = <0>; };
		ethernet-phy@1 { reg = <1>; };
		ethernet-phy@2 { reg = <2>; };
		ethernet-phy@3 { reg = <3>; };
		ethernet-phy@4 { reg = <4>; };
		ethernet-phy@5 { reg = <5>; };
		ethernet-phy@6 { reg = <6>; };
		ethernet-phy@7 { reg = <7>; };
	};

	/* [34] MDC=GPIO3_C1(113)  MDIO=GPIO3_C0(112) */
	mdio_gpio34: mdio-gpio-34 {
		compatible = "virtual,mdio-gpio";
		#address-cells = <1>;
		#size-cells = <0>;
		gpios = <&gpio3 17 GPIO_ACTIVE_HIGH>,
		        <&gpio3 16 GPIO_ACTIVE_HIGH>;
		ethernet-phy@0 { reg = <0>; };
		ethernet-phy@1 { reg = <1>; };
		ethernet-phy@2 { reg = <2>; };
		ethernet-phy@3 { reg = <3>; };
		ethernet-phy@4 { reg = <4>; };
		ethernet-phy@5 { reg = <5>; };
		ethernet-phy@6 { reg = <6>; };
		ethernet-phy@7 { reg = <7>; };
	};

	/* [35] MDC=GPIO3_C1(113)  MDIO=GPIO3_C2(114) */
	mdio_gpio35: mdio-gpio-35 {
		compatible = "virtual,mdio-gpio";
		#address-cells = <1>;
		#size-cells = <0>;
		gpios = <&gpio3 17 GPIO_ACTIVE_HIGH>,
		        <&gpio3 18 GPIO_ACTIVE_HIGH>;
		ethernet-phy@0 { reg = <0>; };
		ethernet-phy@1 { reg = <1>; };
		ethernet-phy@2 { reg = <2>; };
		ethernet-phy@3 { reg = <3>; };
		ethernet-phy@4 { reg = <4>; };
		ethernet-phy@5 { reg = <5>; };
		ethernet-phy@6 { reg = <6>; };
		ethernet-phy@7 { reg = <7>; };
	};

	/* [36] MDC=GPIO3_C2(114)  MDIO=GPIO3_C1(113) */
	mdio_gpio36: mdio-gpio-36 {
		compatible = "virtual,mdio-gpio";
		#address-cells = <1>;
		#size-cells = <0>;
		gpios = <&gpio3 18 GPIO_ACTIVE_HIGH>,
		        <&gpio3 17 GPIO_ACTIVE_HIGH>;
		ethernet-phy@0 { reg = <0>; };
		ethernet-phy@1 { reg = <1>; };
		ethernet-phy@2 { reg = <2>; };
		ethernet-phy@3 { reg = <3>; };
		ethernet-phy@4 { reg = <4>; };
		ethernet-phy@5 { reg = <5>; };
		ethernet-phy@6 { reg = <6>; };
		ethernet-phy@7 { reg = <7>; };
	};

	/* [37] MDC=GPIO3_C2(114)  MDIO=GPIO3_C3(115) */
	mdio_gpio37: mdio-gpio-37 {
		compatible = "virtual,mdio-gpio";
		#address-cells = <1>;
		#size-cells = <0>;
		gpios = <&gpio3 18 GPIO_ACTIVE_HIGH>,
		        <&gpio3 19 GPIO_ACTIVE_HIGH>;
		ethernet-phy@0 { reg = <0>; };
		ethernet-phy@1 { reg = <1>; };
		ethernet-phy@2 { reg = <2>; };
		ethernet-phy@3 { reg = <3>; };
		ethernet-phy@4 { reg = <4>; };
		ethernet-phy@5 { reg = <5>; };
		ethernet-phy@6 { reg = <6>; };
		ethernet-phy@7 { reg = <7>; };
	};

	/* [38] MDC=GPIO3_C3(115)  MDIO=GPIO3_C2(114) */
	mdio_gpio38: mdio-gpio-38 {
		compatible = "virtual,mdio-gpio";
		#address-cells = <1>;
		#size-cells = <0>;
		gpios = <&gpio3 19 GPIO_ACTIVE_HIGH>,
		        <&gpio3 18 GPIO_ACTIVE_HIGH>;
		ethernet-phy@0 { reg = <0>; };
		ethernet-phy@1 { reg = <1>; };
		ethernet-phy@2 { reg = <2>; };
		ethernet-phy@3 { reg = <3>; };
		ethernet-phy@4 { reg = <4>; };
		ethernet-phy@5 { reg = <5>; };
		ethernet-phy@6 { reg = <6>; };
		ethernet-phy@7 { reg = <7>; };
	};

	/* [39] MDC=GPIO3_C3(115)  MDIO=GPIO3_C4(116) */
	mdio_gpio39: mdio-gpio-39 {
		compatible = "virtual,mdio-gpio";
		#address-cells = <1>;
		#size-cells = <0>;
		gpios = <&gpio3 19 GPIO_ACTIVE_HIGH>,
		        <&gpio3 20 GPIO_ACTIVE_HIGH>;
		ethernet-phy@0 { reg = <0>; };
		ethernet-phy@1 { reg = <1>; };
		ethernet-phy@2 { reg = <2>; };
		ethernet-phy@3 { reg = <3>; };
		ethernet-phy@4 { reg = <4>; };
		ethernet-phy@5 { reg = <5>; };
		ethernet-phy@6 { reg = <6>; };
		ethernet-phy@7 { reg = <7>; };
	};

	/* [40] MDC=GPIO3_C4(116)  MDIO=GPIO3_C3(115) */
	mdio_gpio40: mdio-gpio-40 {
		compatible = "virtual,mdio-gpio";
		#address-cells = <1>;
		#size-cells = <0>;
		gpios = <&gpio3 20 GPIO_ACTIVE_HIGH>,
		        <&gpio3 19 GPIO_ACTIVE_HIGH>;
		ethernet-phy@0 { reg = <0>; };
		ethernet-phy@1 { reg = <1>; };
		ethernet-phy@2 { reg = <2>; };
		ethernet-phy@3 { reg = <3>; };
		ethernet-phy@4 { reg = <4>; };
		ethernet-phy@5 { reg = <5>; };
		ethernet-phy@6 { reg = <6>; };
		ethernet-phy@7 { reg = <7>; };
	};

	/* [41] MDC=GPIO3_C4(116)  MDIO=GPIO3_C5(117) */
	mdio_gpio41: mdio-gpio-41 {
		compatible = "virtual,mdio-gpio";
		#address-cells = <1>;
		#size-cells = <0>;
		gpios = <&gpio3 20 GPIO_ACTIVE_HIGH>,
		        <&gpio3 21 GPIO_ACTIVE_HIGH>;
		ethernet-phy@0 { reg = <0>; };
		ethernet-phy@1 { reg = <1>; };
		ethernet-phy@2 { reg = <2>; };
		ethernet-phy@3 { reg = <3>; };
		ethernet-phy@4 { reg = <4>; };
		ethernet-phy@5 { reg = <5>; };
		ethernet-phy@6 { reg = <6>; };
		ethernet-phy@7 { reg = <7>; };
	};

	/* [42] MDC=GPIO3_C5(117)  MDIO=GPIO3_C4(116) */
	mdio_gpio42: mdio-gpio-42 {
		compatible = "virtual,mdio-gpio";
		#address-cells = <1>;
		#size-cells = <0>;
		gpios = <&gpio3 21 GPIO_ACTIVE_HIGH>,
		        <&gpio3 20 GPIO_ACTIVE_HIGH>;
		ethernet-phy@0 { reg = <0>; };
		ethernet-phy@1 { reg = <1>; };
		ethernet-phy@2 { reg = <2>; };
		ethernet-phy@3 { reg = <3>; };
		ethernet-phy@4 { reg = <4>; };
		ethernet-phy@5 { reg = <5>; };
		ethernet-phy@6 { reg = <6>; };
		ethernet-phy@7 { reg = <7>; };
	};

	/* [43] MDC=GPIO3_C5(117)  MDIO=GPIO3_C6(118) */
	mdio_gpio43: mdio-gpio-43 {
		compatible = "virtual,mdio-gpio";
		#address-cells = <1>;
		#size-cells = <0>;
		gpios = <&gpio3 21 GPIO_ACTIVE_HIGH>,
		        <&gpio3 22 GPIO_ACTIVE_HIGH>;
		ethernet-phy@0 { reg = <0>; };
		ethernet-phy@1 { reg = <1>; };
		ethernet-phy@2 { reg = <2>; };
		ethernet-phy@3 { reg = <3>; };
		ethernet-phy@4 { reg = <4>; };
		ethernet-phy@5 { reg = <5>; };
		ethernet-phy@6 { reg = <6>; };
		ethernet-phy@7 { reg = <7>; };
	};

	/* [44] MDC=GPIO3_C6(118)  MDIO=GPIO3_C5(117) */
	mdio_gpio44: mdio-gpio-44 {
		compatible = "virtual,mdio-gpio";
		#address-cells = <1>;
		#size-cells = <0>;
		gpios = <&gpio3 22 GPIO_ACTIVE_HIGH>,
		        <&gpio3 21 GPIO_ACTIVE_HIGH>;
		ethernet-phy@0 { reg = <0>; };
		ethernet-phy@1 { reg = <1>; };
		ethernet-phy@2 { reg = <2>; };
		ethernet-phy@3 { reg = <3>; };
		ethernet-phy@4 { reg = <4>; };
		ethernet-phy@5 { reg = <5>; };
		ethernet-phy@6 { reg = <6>; };
		ethernet-phy@7 { reg = <7>; };
	};

	/* [45] MDC=GPIO3_C6(118)  MDIO=GPIO3_C7(119) */
	mdio_gpio45: mdio-gpio-45 {
		compatible = "virtual,mdio-gpio";
		#address-cells = <1>;
		#size-cells = <0>;
		gpios = <&gpio3 22 GPIO_ACTIVE_HIGH>,
		        <&gpio3 23 GPIO_ACTIVE_HIGH>;
		ethernet-phy@0 { reg = <0>; };
		ethernet-phy@1 { reg = <1>; };
		ethernet-phy@2 { reg = <2>; };
		ethernet-phy@3 { reg = <3>; };
		ethernet-phy@4 { reg = <4>; };
		ethernet-phy@5 { reg = <5>; };
		ethernet-phy@6 { reg = <6>; };
		ethernet-phy@7 { reg = <7>; };
	};

	/* [46] MDC=GPIO3_C7(119)  MDIO=GPIO3_C6(118) */
	mdio_gpio46: mdio-gpio-46 {
		compatible = "virtual,mdio-gpio";
		#address-cells = <1>;
		#size-cells = <0>;
		gpios = <&gpio3 23 GPIO_ACTIVE_HIGH>,
		        <&gpio3 22 GPIO_ACTIVE_HIGH>;
		ethernet-phy@0 { reg = <0>; };
		ethernet-phy@1 { reg = <1>; };
		ethernet-phy@2 { reg = <2>; };
		ethernet-phy@3 { reg = <3>; };
		ethernet-phy@4 { reg = <4>; };
		ethernet-phy@5 { reg = <5>; };
		ethernet-phy@6 { reg = <6>; };
		ethernet-phy@7 { reg = <7>; };
	};

	/* [47] MDC=GPIO3_C7(119)  MDIO=GPIO3_D0(120) */
	mdio_gpio47: mdio-gpio-47 {
		compatible = "virtual,mdio-gpio";
		#address-cells = <1>;
		#size-cells = <0>;
		gpios = <&gpio3 23 GPIO_ACTIVE_HIGH>,
		        <&gpio3 24 GPIO_ACTIVE_HIGH>;
		ethernet-phy@0 { reg = <0>; };
		ethernet-phy@1 { reg = <1>; };
		ethernet-phy@2 { reg = <2>; };
		ethernet-phy@3 { reg = <3>; };
		ethernet-phy@4 { reg = <4>; };
		ethernet-phy@5 { reg = <5>; };
		ethernet-phy@6 { reg = <6>; };
		ethernet-phy@7 { reg = <7>; };
	};

	/* [48] MDC=GPIO3_D0(120)  MDIO=GPIO3_C7(119) */
	mdio_gpio48: mdio-gpio-48 {
		compatible = "virtual,mdio-gpio";
		#address-cells = <1>;
		#size-cells = <0>;
		gpios = <&gpio3 24 GPIO_ACTIVE_HIGH>,
		        <&gpio3 23 GPIO_ACTIVE_HIGH>;
		ethernet-phy@0 { reg = <0>; };
		ethernet-phy@1 { reg = <1>; };
		ethernet-phy@2 { reg = <2>; };
		ethernet-phy@3 { reg = <3>; };
		ethernet-phy@4 { reg = <4>; };
		ethernet-phy@5 { reg = <5>; };
		ethernet-phy@6 { reg = <6>; };
		ethernet-phy@7 { reg = <7>; };
	};

	/* [49] MDC=GPIO3_D0(120)  MDIO=GPIO3_D1(121) */
	mdio_gpio49: mdio-gpio-49 {
		compatible = "virtual,mdio-gpio";
		#address-cells = <1>;
		#size-cells = <0>;
		gpios = <&gpio3 24 GPIO_ACTIVE_HIGH>,
		        <&gpio3 25 GPIO_ACTIVE_HIGH>;
		ethernet-phy@0 { reg = <0>; };
		ethernet-phy@1 { reg = <1>; };
		ethernet-phy@2 { reg = <2>; };
		ethernet-phy@3 { reg = <3>; };
		ethernet-phy@4 { reg = <4>; };
		ethernet-phy@5 { reg = <5>; };
		ethernet-phy@6 { reg = <6>; };
		ethernet-phy@7 { reg = <7>; };
	};

	/* [50] MDC=GPIO3_D1(121)  MDIO=GPIO3_D2(122) */
	mdio_gpio50: mdio-gpio-50 {
		compatible = "virtual,mdio-gpio";
		#address-cells = <1>;
		#size-cells = <0>;
		gpios = <&gpio3 25 GPIO_ACTIVE_HIGH>,
		        <&gpio3 26 GPIO_ACTIVE_HIGH>;
		ethernet-phy@0 { reg = <0>; };
		ethernet-phy@1 { reg = <1>; };
		ethernet-phy@2 { reg = <2>; };
		ethernet-phy@3 { reg = <3>; };
		ethernet-phy@4 { reg = <4>; };
		ethernet-phy@5 { reg = <5>; };
		ethernet-phy@6 { reg = <6>; };
		ethernet-phy@7 { reg = <7>; };
	};

	/* [51] MDC=GPIO3_D2(122)  MDIO=GPIO3_D1(121) */
	mdio_gpio51: mdio-gpio-51 {
		compatible = "virtual,mdio-gpio";
		#address-cells = <1>;
		#size-cells = <0>;
		gpios = <&gpio3 26 GPIO_ACTIVE_HIGH>,
		        <&gpio3 25 GPIO_ACTIVE_HIGH>;
		ethernet-phy@0 { reg = <0>; };
		ethernet-phy@1 { reg = <1>; };
		ethernet-phy@2 { reg = <2>; };
		ethernet-phy@3 { reg = <3>; };
		ethernet-phy@4 { reg = <4>; };
		ethernet-phy@5 { reg = <5>; };
		ethernet-phy@6 { reg = <6>; };
		ethernet-phy@7 { reg = <7>; };
	};

	/* [52] MDC=GPIO3_D2(122)  MDIO=GPIO3_D3(123) */
	mdio_gpio52: mdio-gpio-52 {
		compatible = "virtual,mdio-gpio";
		#address-cells = <1>;
		#size-cells = <0>;
		gpios = <&gpio3 26 GPIO_ACTIVE_HIGH>,
		        <&gpio3 27 GPIO_ACTIVE_HIGH>;
		ethernet-phy@0 { reg = <0>; };
		ethernet-phy@1 { reg = <1>; };
		ethernet-phy@2 { reg = <2>; };
		ethernet-phy@3 { reg = <3>; };
		ethernet-phy@4 { reg = <4>; };
		ethernet-phy@5 { reg = <5>; };
		ethernet-phy@6 { reg = <6>; };
		ethernet-phy@7 { reg = <7>; };
	};

	/* [53] MDC=GPIO3_D3(123)  MDIO=GPIO3_D2(122) */
	mdio_gpio53: mdio-gpio-53 {
		compatible = "virtual,mdio-gpio";
		#address-cells = <1>;
		#size-cells = <0>;
		gpios = <&gpio3 27 GPIO_ACTIVE_HIGH>,
		        <&gpio3 26 GPIO_ACTIVE_HIGH>;
		ethernet-phy@0 { reg = <0>; };
		ethernet-phy@1 { reg = <1>; };
		ethernet-phy@2 { reg = <2>; };
		ethernet-phy@3 { reg = <3>; };
		ethernet-phy@4 { reg = <4>; };
		ethernet-phy@5 { reg = <5>; };
		ethernet-phy@6 { reg = <6>; };
		ethernet-phy@7 { reg = <7>; };
	};

	/* [54] MDC=GPIO3_D3(123)  MDIO=GPIO3_D4(124) */
	mdio_gpio54: mdio-gpio-54 {
		compatible = "virtual,mdio-gpio";
		#address-cells = <1>;
		#size-cells = <0>;
		gpios = <&gpio3 27 GPIO_ACTIVE_HIGH>,
		        <&gpio3 28 GPIO_ACTIVE_HIGH>;
		ethernet-phy@0 { reg = <0>; };
		ethernet-phy@1 { reg = <1>; };
		ethernet-phy@2 { reg = <2>; };
		ethernet-phy@3 { reg = <3>; };
		ethernet-phy@4 { reg = <4>; };
		ethernet-phy@5 { reg = <5>; };
		ethernet-phy@6 { reg = <6>; };
		ethernet-phy@7 { reg = <7>; };
	};

	/* [55] MDC=GPIO3_D4(124)  MDIO=GPIO3_D3(123) */
	mdio_gpio55: mdio-gpio-55 {
		compatible = "virtual,mdio-gpio";
		#address-cells = <1>;
		#size-cells = <0>;
		gpios = <&gpio3 28 GPIO_ACTIVE_HIGH>,
		        <&gpio3 27 GPIO_ACTIVE_HIGH>;
		ethernet-phy@0 { reg = <0>; };
		ethernet-phy@1 { reg = <1>; };
		ethernet-phy@2 { reg = <2>; };
		ethernet-phy@3 { reg = <3>; };
		ethernet-phy@4 { reg = <4>; };
		ethernet-phy@5 { reg = <5>; };
		ethernet-phy@6 { reg = <6>; };
		ethernet-phy@7 { reg = <7>; };
	};

	/* [56] MDC=GPIO3_D4(124)  MDIO=GPIO3_D5(125) */
	mdio_gpio56: mdio-gpio-56 {
		compatible = "virtual,mdio-gpio";
		#address-cells = <1>;
		#size-cells = <0>;
		gpios = <&gpio3 28 GPIO_ACTIVE_HIGH>,
		        <&gpio3 29 GPIO_ACTIVE_HIGH>;
		ethernet-phy@0 { reg = <0>; };
		ethernet-phy@1 { reg = <1>; };
		ethernet-phy@2 { reg = <2>; };
		ethernet-phy@3 { reg = <3>; };
		ethernet-phy@4 { reg = <4>; };
		ethernet-phy@5 { reg = <5>; };
		ethernet-phy@6 { reg = <6>; };
		ethernet-phy@7 { reg = <7>; };
	};

	/* [57] MDC=GPIO3_D5(125)  MDIO=GPIO3_D4(124) */
	mdio_gpio57: mdio-gpio-57 {
		compatible = "virtual,mdio-gpio";
		#address-cells = <1>;
		#size-cells = <0>;
		gpios = <&gpio3 29 GPIO_ACTIVE_HIGH>,
		        <&gpio3 28 GPIO_ACTIVE_HIGH>;
		ethernet-phy@0 { reg = <0>; };
		ethernet-phy@1 { reg = <1>; };
		ethernet-phy@2 { reg = <2>; };
		ethernet-phy@3 { reg = <3>; };
		ethernet-phy@4 { reg = <4>; };
		ethernet-phy@5 { reg = <5>; };
		ethernet-phy@6 { reg = <6>; };
		ethernet-phy@7 { reg = <7>; };
	};

	/* [58] MDC=GPIO3_D5(125)  MDIO=GPIO3_D6(126) */
	mdio_gpio58: mdio-gpio-58 {
		compatible = "virtual,mdio-gpio";
		#address-cells = <1>;
		#size-cells = <0>;
		gpios = <&gpio3 29 GPIO_ACTIVE_HIGH>,
		        <&gpio3 30 GPIO_ACTIVE_HIGH>;
		ethernet-phy@0 { reg = <0>; };
		ethernet-phy@1 { reg = <1>; };
		ethernet-phy@2 { reg = <2>; };
		ethernet-phy@3 { reg = <3>; };
		ethernet-phy@4 { reg = <4>; };
		ethernet-phy@5 { reg = <5>; };
		ethernet-phy@6 { reg = <6>; };
		ethernet-phy@7 { reg = <7>; };
	};

	/* [59] MDC=GPIO3_D6(126)  MDIO=GPIO3_D5(125) */
	mdio_gpio59: mdio-gpio-59 {
		compatible = "virtual,mdio-gpio";
		#address-cells = <1>;
		#size-cells = <0>;
		gpios = <&gpio3 30 GPIO_ACTIVE_HIGH>,
		        <&gpio3 29 GPIO_ACTIVE_HIGH>;
		ethernet-phy@0 { reg = <0>; };
		ethernet-phy@1 { reg = <1>; };
		ethernet-phy@2 { reg = <2>; };
		ethernet-phy@3 { reg = <3>; };
		ethernet-phy@4 { reg = <4>; };
		ethernet-phy@5 { reg = <5>; };
		ethernet-phy@6 { reg = <6>; };
		ethernet-phy@7 { reg = <7>; };
	};

	/* [60] MDC=GPIO3_D6(126)  MDIO=GPIO3_D7(127) */
	mdio_gpio60: mdio-gpio-60 {
		compatible = "virtual,mdio-gpio";
		#address-cells = <1>;
		#size-cells = <0>;
		gpios = <&gpio3 30 GPIO_ACTIVE_HIGH>,
		        <&gpio3 31 GPIO_ACTIVE_HIGH>;
		ethernet-phy@0 { reg = <0>; };
		ethernet-phy@1 { reg = <1>; };
		ethernet-phy@2 { reg = <2>; };
		ethernet-phy@3 { reg = <3>; };
		ethernet-phy@4 { reg = <4>; };
		ethernet-phy@5 { reg = <5>; };
		ethernet-phy@6 { reg = <6>; };
		ethernet-phy@7 { reg = <7>; };
	};

	/* [61] MDC=GPIO3_D7(127)  MDIO=GPIO3_D6(126) */
	mdio_gpio61: mdio-gpio-61 {
		compatible = "virtual,mdio-gpio";
		#address-cells = <1>;
		#size-cells = <0>;
		gpios = <&gpio3 31 GPIO_ACTIVE_HIGH>,
		        <&gpio3 30 GPIO_ACTIVE_HIGH>;
		ethernet-phy@0 { reg = <0>; };
		ethernet-phy@1 { reg = <1>; };
		ethernet-phy@2 { reg = <2>; };
		ethernet-phy@3 { reg = <3>; };
		ethernet-phy@4 { reg = <4>; };
		ethernet-phy@5 { reg = <5>; };
		ethernet-phy@6 { reg = <6>; };
		ethernet-phy@7 { reg = <7>; };
	};


	gpio-keys {
		compatible = "gpio-keys";
		autorepeat;
		key-power {
			gpios = <&gpio0 RK_PA4 GPIO_ACTIVE_LOW>;
			linux,code = <KEY_POWER>;
			label = "GPIO Key Power";
			linux,input-type = <1>;
			wakeup-source;
			debounce-interval = <100>;
		};
	};

	gpio-leds {
		compatible = "gpio-leds";
		led-blue {
			label = "adesk:blue:status";
			gpios = <&gpio0 RK_PB6 GPIO_ACTIVE_LOW>;
			default-state = "off";
		};
		led-red {
			label = "adesk:red:power";
			gpios = <&gpio0 RK_PB7 GPIO_ACTIVE_HIGH>;
			default-state = "off";
		};
	};

	ir_recv: ir-receiver {
		compatible = "gpio-ir-receiver";
		gpios = <&gpio0 RK_PB2 GPIO_ACTIVE_LOW>;
		pinctrl-names = "default";
		pinctrl-0 = <&ir_recv_pin>;
	};

	sound {
		compatible = "simple-audio-card";
		simple-audio-card,name = "RK_ES8316";
		simple-audio-card,format = "i2s";
		simple-audio-card,mclk-fs = <256>;
		simple-audio-card,cpu { sound-dai = <&i2s0>; };
		simple-audio-card,codec { sound-dai = <&es8316>; };
	};
};

&cpu0 { cpu-supply = <&vdd_cpu>; };
&cpu1 { cpu-supply = <&vdd_cpu>; };
&cpu2 { cpu-supply = <&vdd_cpu>; };
&cpu3 { cpu-supply = <&vdd_cpu>; };

&i2c1 {
	status = "okay";
	clock-frequency = <400000>;

	rk808: pmic@1b {
		compatible = "rockchip,rk808";
		reg = <0x1b>;
		interrupt-parent = <&gpio0>;
		interrupts = <RK_PB3 IRQ_TYPE_LEVEL_LOW>;
		pinctrl-names = "default";
		pinctrl-0 = <&pmic_int>;
		rockchip,system-power-controller;
		wakeup-source;
		#clock-cells = <1>;
		clock-output-names = "rk808-clkout1", "rk808-clkout2";

		vcc1-supply = <&vcc_sys>;
		vcc2-supply = <&vcc_sys>;
		vcc3-supply = <&vcc_sys>;
		vcc4-supply = <&vcc_sys>;
		vcc6-supply = <&vcc_sys>;
		vcc7-supply = <&vcc_sys>;
		vcc8-supply = <&vcc_io>;
		vcc9-supply = <&vcc_io>;

		regulators {
			vdd_cpu: DCDC_REG1 { regulator-always-on; regulator-boot-on; regulator-min-microvolt = <1100000>; regulator-max-microvolt = <1100000>; regulator-name = "vdd_arm"; };
			vdd_core: DCDC_REG2 { regulator-always-on; regulator-boot-on; regulator-min-microvolt = <1100000>; regulator-max-microvolt = <1100000>; regulator-name = "vdd_core"; };
			vcc_ddr: DCDC_REG3 { regulator-always-on; regulator-boot-on; regulator-min-microvolt = <1200000>; regulator-max-microvolt = <1200000>; regulator-name = "vcc_ddr"; };
			vcc_io_rk: DCDC_REG4 { regulator-always-on; regulator-boot-on; regulator-min-microvolt = <3300000>; regulator-max-microvolt = <3300000>; regulator-name = "vcc_io"; };
			vcc_33: LDO_REG1 { regulator-always-on; regulator-boot-on; regulator-min-microvolt = <3300000>; regulator-max-microvolt = <3300000>; regulator-name = "vcc_33"; };
			vcc_18: LDO_REG2 { regulator-always-on; regulator-boot-on; regulator-min-microvolt = <1800000>; regulator-max-microvolt = <1800000>; regulator-name = "vcc_18"; };
			vcc_10: LDO_REG3 { regulator-always-on; regulator-boot-on; regulator-min-microvolt = <1000000>; regulator-max-microvolt = <1000000>; regulator-name = "vcc_10"; };
			vcc_18_2: LDO_REG4 { regulator-always-on; regulator-boot-on; regulator-min-microvolt = <1800000>; regulator-max-microvolt = <1800000>; regulator-name = "vcc_18_2"; };
			vcc_28: LDO_REG5 { regulator-always-on; regulator-boot-on; regulator-min-microvolt = <2800000>; regulator-max-microvolt = <2800000>; regulator-name = "vcc_28"; };
			vcc_12: LDO_REG6 { regulator-always-on; regulator-boot-on; regulator-min-microvolt = <1200000>; regulator-max-microvolt = <1200000>; regulator-name = "vcc_12"; };
			vcc_18_3: LDO_REG7 { regulator-always-on; regulator-boot-on; regulator-min-microvolt = <1800000>; regulator-max-microvolt = <1800000>; regulator-name = "vcc_18_3"; };
			vcc_33_2: LDO_REG8 { regulator-always-on; regulator-boot-on; regulator-min-microvolt = <3300000>; regulator-max-microvolt = <3300000>; regulator-name = "vcc_33_2"; };
		};
	};

	hym8563: rtc@51 {
		compatible = "haoyu,hym8563";
		reg = <0x51>;
		interrupt-parent = <&gpio0>;
		interrupts = <RK_PB5 IRQ_TYPE_EDGE_FALLING>;
		pinctrl-names = "default";
		pinctrl-0 = <&rtc_int>;
		#clock-cells = <0>;
		clock-output-names = "xin32k";
		wakeup-source;
	};
};

/* eMMC 控制器 */
&emmc {
	bus-width = <8>;
	cap-mmc-highspeed;
	non-removable;
	pinctrl-names = "default";
	pinctrl-0 = <&emmc_clk>, <&emmc_cmd>, <&emmc_rst>;
	vmmc-supply = <&vcc_io>;
	status = "okay";
};

/* SD/TF 卡槽控制器
 *
 * 【第十轮改动：status okay → disabled】
 * 本机（aDesk-STD-200H-s 瘦客户机）主板上没有 SD/TF 卡槽，sd0 那组引脚
 * （sd0_clk/cmd/d0~d3/cd）没有引出到任何连接器。保持 okay 的代价是：
 *   1) 每次启动都注册一个不可能有卡的 host，做一次 400kHz 探测（ttl-rz9 里
 *      "mmc_host mmc0: Bus speed ... 400000Hz" 之后就没有下文，白跑一遍）；
 *   2) pinctrl 会把 sd0 那组脚按 SD 功能配置掉。若这块板子把其中某几根脚
 *      复用成了别的用途（瘦客户机常见做法），就是潜在冲突。
 * 所以直接关掉。原来的配置用注释保留，将来若要接 SD 卡或 SDIO WiFi，
 * 把 status 改回 "okay" 即可。
 *
 * 【为什么关掉它不会变成 mmcblk0】
 * mmc 控制器的编号不是按 probe 顺序，而是按 aliases：
 *   drivers/mmc/core/host.c（v6.12）：
 *     alias_id = of_alias_get_id(dev->of_node, "mmc");
 *     if (alias_id >= 0) index = alias_id;
 * 本 dts 的 aliases 里写了 mmc1 = &emmc，所以 eMMC 固定是 mmc1 →
 * /dev/mmcblk1，parameter.txt 的 root=/dev/mmcblk1p1 继续有效。
 * 千万不要把 mmc1 这条别名删掉或改成 mmc0（已本地核过 6.12 源码）。
 */
&mmc0 {
	bus-width = <4>;
	cap-mmc-highspeed;
	cap-sd-highspeed;
	disable-wp;
	pinctrl-names = "default";
	pinctrl-0 = <&sd0_clk>, <&sd0_cmd>, <&sd0_cd>, <&sd0_bus4>;
	vmmc-supply = <&vcc_io>;
	// status = "okay";          // 原值（保留备查）
	status = "disabled";          // 本机无 SD/TF 卡槽，见上方说明
};

&emac {
	/* ---- 第二十二轮：属性名从 phy-handle 改成 phy（本轮唯一改动）----
	 * 原值（保留备查）：phy-handle = <&phy0>;
	 *
	 * 为什么必须改（6.12 源码，drivers/net/ethernet/arc/emac_main.c:869）：
	 *   phy_node = of_parse_phandle(dev->of_node, "phy", 0);
	 *   if (!phy_node) {
	 *           dev_err(dev, "failed to retrieve phy description from device tree");
	 *           return -ENODEV;
	 *   }
	 * 驱动找的是名为 "phy" 的 phandle，而 "phy-handle" 是 stmmac/其他驱动的写法。
	 * 属性名对不上 → 直接返回 -ENODEV(-19) → 网卡根本注册不上，
	 * 于是 /sys/class/net 里只有 lo 和 sit0（sit0 是 IPv6 隧道占位设备）。
	 * 实机日志完全对得上：
	 *   rockchip_emac 10204000.ethernet: failed to retrieve phy description from device tree
	 *   rockchip_emac 10204000.ethernet: failed to probe arc emac (-19)
	 *
	 * 另一个"看着像错、其实无害"的日志是 "no regulator found"，
	 * 出自 emac_rockchip.c:162 的 devm_regulator_get_optional()，可选，忽略即可。
	 *
	 * phy-mode 本来不用写（基节点 rk3xxx.dtsi:203 已有 phy-mode = "rmii"，
	 * 且 emac_rockchip.c:121 只接受 RMII，继承下来正好）；这里显式再写一遍，
	 * 是为了万一将来换基树/换版本时该属性丢失 —— 值与原继承值完全相同，
	 * 属于"写了不改行为"的保险，参考朋友那份 rk3188-adesk.dts:199。
	 */
	phy-mode = "rmii";

	/* 参考朋友那份 rk3188-adesk.dts:200 补上 PHY 供电引用。
	 * 原状（无此行）会打印 "rockchip_emac 10204000.ethernet: no regulator found"，
	 * 该告警来自 emac_rockchip.c:162 的 devm_regulator_get_optional(dev, "phy")，
	 * 本身不致命；补上后这行噪音消失，并把 3.3V IO 电源正式挂到 PHY 上。
	 * vcc_io 在本 dts 里是 regulator-fixed、regulator-always-on，enable 是空操作，无风险。
	 */
	phy-supply = <&vcc_io>;

	phy = <&phy0>;          /* 关键：驱动要的是 phy，不是 phy-handle，见上方说明 */
	pinctrl-names = "default";
	/* 原值（保留备查）：pinctrl-0 = <&emac_xfer>, <&emac_mdio>;
	 * GPIOD0/D1 已被 mdio-gpio 当 GPIO 用掉了，这里不能再申请为 EMAC 复用功能，
	 * 否则 pinctrl 会把同一只脚配成两种功能，后者覆盖前者。 */
	pinctrl-0 = <&emac_xfer>;
	status = "okay";

	/* 原值（保留备查）：内部 mdio 子节点，phy0 在这里
	 *   mdio {
	 *           #address-cells = <1>;
	 *           #size-cells = <0>;
	 *           phy0: ethernet-phy@0 { reg = <0>; };
	 *   };
	 * 现在 phy0 移到 root 下的 mdio_gpio 总线里，硬件 MDIO 总线上不再挂 PHY，
	 * 但驱动仍会注册这条空总线（arc_mdio_probe 在没有 mdio 子节点时
	 * 用 emac 节点本身注册），不影响功能。 */
};

&usbphy { status = "okay"; };
&usb_host { status = "okay"; };
&usb_otg { status = "okay"; };

&i2c4 {
	status = "okay";
	clock-frequency = <100000>;
	es8316: codec@10 {
		compatible = "everest,es8316";
		reg = <0x10>;
		clocks = <&cru SCLK_I2S0>;
		clock-names = "mclk";
		#sound-dai-cells = <0>;
	};
};

&i2s0 { status = "okay"; };

&i2c0 {
	status = "okay";
	vga_edid: eeprom@50 { compatible = "atmel,24c02"; reg = <0x50>; pagesize = <16>; };
};

&i2c2 {
	status = "okay";
	hdmi_tx: hdmi@2b { compatible = "vendor,ms7210"; reg = <0x2b>; status = "disabled"; };
	it66121: hdmi-tx@4c { compatible = "ite,it66121"; reg = <0x4c>; status = "disabled"; };
};

&i2c3 { status = "disabled"; };
&vop0 { status = "disabled"; };
&vop1 { status = "disabled"; };

/* ========================================================
 * 串口开启（对照实机 TTL 日志修正）
 * 日志证据：earlycon at MMIO 0x20064000（= uart2），8250 probe 0x10124000（= uart0）；
 * TTL 物理接在 uart2，故正式 console 用 &uart2（ttyS2）。
 * 原代码开启的是 &uart0；现改为 &uart2，uart0 保持 dtsi 默认 disabled。
 * ======================================================== */
/* 原始（误改）：&uart0 { status = "okay"; }; */
&uart2 {
	status = "okay";
};

&pinctrl {
	/* ----------------------------------------------------------------
	 * 【第二十四轮修正：group 必须挂在"函数节点"下面，不能直接放顶层】
	 *
	 * 上一版把 emac_mdio_gpio 直接写成 &pinctrl 的子节点，实机日志报：
	 *   rockchip-pinctrl pinctrl: unable to find group for node emac-mdio-gpio
	 * 原因在 pinctrl-rockchip.c 的 rockchip_pinctrl_parse_functions()：
	 *   func->ngroups = of_get_child_count(np);
	 *   if (func->ngroups <= 0) return 0;     ← 没有子节点就整个跳过
	 * 也就是说 pinctrl 顶层每个子节点被当成"一个函数"，它的**子节点**才是
	 * 真正的 group。group 直接放顶层 → 既不注册 group，也查不到这个 phandle，
	 * 于是 mdio-gpio 节点 pinctrl-0 应用失败、驱动没 probe，PHY 根本没注册，
	 * emac 拿着 phy0 去找人自然 of_phy_connect() failed (-19)。
	 *
	 * 这里把 group 挪进 dtsi 里本来就有的 emac 函数节点（DT 同名节点自动合并），
	 * 和上面 pmic / hym8563 / ir-receiver 的写法保持一致。
	 * ---------------------------------------------------------------- */
	emac {
		/* D1 = MDC 只输出，不配上下拉；D0 = MDIO 双向，配上拉
		 * （双向开漏线配上拉，与板上外部上拉并联不会出问题） */
		emac_mdio_gpio: emac-mdio-gpio {
			rockchip,pins = <3 RK_PD1 RK_FUNC_GPIO &pcfg_pull_none>,
			                <3 RK_PD0 RK_FUNC_GPIO &pcfg_pull_up>;
		};
	};

	pmic { pmic_int: pmic-int { rockchip,pins = <0 RK_PB3 RK_FUNC_GPIO &pcfg_pull_up>; }; };
	hym8563 { rtc_int: rtc-int { rockchip,pins = <0 RK_PB5 RK_FUNC_GPIO &pcfg_pull_up>; }; };
	ir-receiver { ir_recv_pin: ir-recv-pin { rockchip,pins = <0 RK_PB2 RK_FUNC_GPIO &pcfg_pull_none>; }; };
};
